# KM1M7CF13 register map
Vendor: Nuvoton Technology Corporation Japan; Series: KM1M7CF; File version: 1.0.3
CPU: CM7 r1p2, little endian, MPU, FPU, double-precision FPU, I-cache, D-cache, ITCM, DTCM, 4 interrupt priority bits
Registers are 32-bit, read-write, no defined reset value unless marked. A register's access mark holds for its fields unless they carry their own. Offsets are from the block's base; [hi:lo] are bit positions; {n}, {i} and the like mark numbered series; 'fields as' and 'values as' point back to an identical list.

## MFA — Multi Feedback Assist
Base 0x40025000
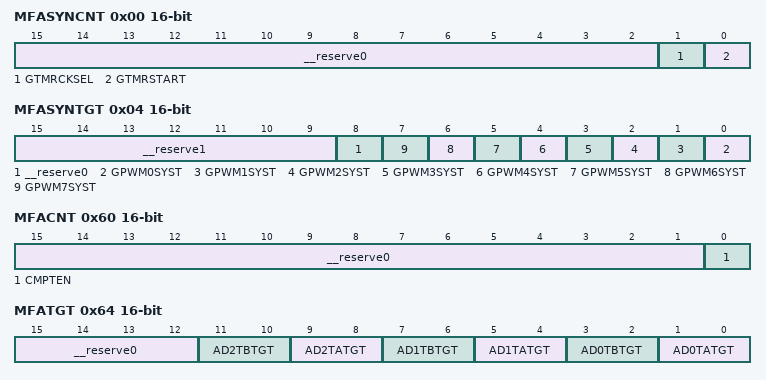
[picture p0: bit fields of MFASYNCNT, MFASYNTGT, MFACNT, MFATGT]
0x00 MFASYNCNT 16-bit access per field — Synchronous Start Control Register
  [15:2] __reserve0 ro — "0" is always read out.
  [1] GTMRCKSEL rw — Selection of count clock at global timer
  [0] GTMRSTART rw — Enable global timer operation
0x04 MFASYNTGT 16-bit access per field — Synchronous Start Target Selection Register
  [15:9] __reserve1 ro — "0" is always read out.
  [8] __reserve0 rw — This bit must be set to "0".
  [n] GPWM{n}SYST rw (n=0..7) — GPWM{n} synchronous start selection
0x08 MFAGTIMERSET 16-bit — Global Timer Cycle Set Register
  [15:0] GTIMERST — Set global timer count cycle
{0x10+4i} MFAGPWM{i}DLY 16-bit (i=0..7) — GPWM{i} Synchronous Start Timing set Register
  [15:0] GPWMnDST — Set the count value of the global timer that starts GPWMn.
0x60 MFACNT 16-bit access per field — Conflict Detection Control Register
  [15:1] __reserve0 ro — "0" is always read out.
  [0] CMPTEN rw — Enable operation of Conflict detection/Automatic avoidance function
0x64 MFATGT 16-bit access per field — Conflict Detection A/D Conversion Start Trigger Selection Register
  [15:12] __reserve0 ro — "0" is always read out.
  [11:10] AD2TBTGT rw — Selection of conflict detection and avoidance operation of A/D2 conversion start trigger B
  [9:8] AD2TATGT rw — Selection of conflict detection and avoidance operation of A/D2 conversion start trigger A
  [7:6] AD1TBTGT rw — Selection of conflict detection and avoidance operation of A/D1 conversion start trigger B
  [5:4] AD1TATGT rw — Selection of conflict detection and avoidance operation of A/D1 conversion start trigger A
  [3:2] AD0TBTGT rw — Selection of conflict detection and avoidance operation of A/D0 conversion start trigger B
  [1:0] AD0TATGT rw — Selection of conflict detection and avoidance operation of A/D0 conversion start trigger A
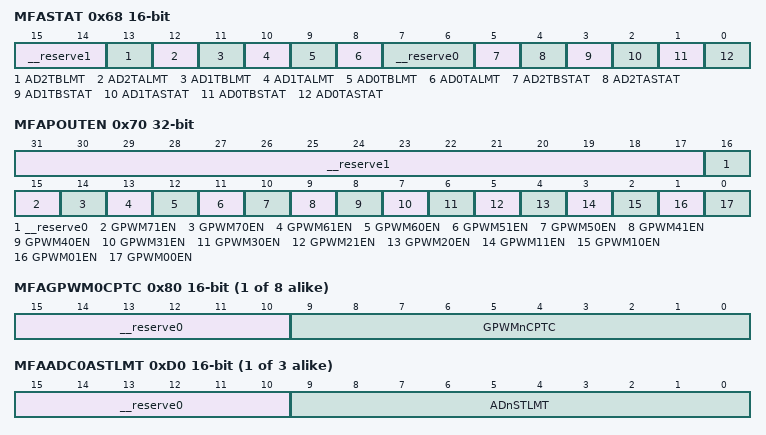
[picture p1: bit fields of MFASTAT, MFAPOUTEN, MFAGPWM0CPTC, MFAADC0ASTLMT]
0x68 MFASTAT 16-bit ro — Conflict Detection Status Register
  [15:14] __reserve1 — "0" is always read out.
  [13] AD2TBLMT — Delay status of A/D2 conversion start trigger B
  [12] AD2TALMT — Delay status of A/D2 conversion start trigger A
  [11] AD1TBLMT — Delay status of A/D1 conversion start trigger B
  [10] AD1TALMT — Delay status of A/D1 conversion start trigger A
  [9] AD0TBLMT — Delay status of A/D0 conversion start trigger B
  [8] AD0TALMT — Delay status of A/D0 conversion start trigger A
  [7:6] __reserve0 — "0" is always read out.
  [5] AD2TBSTAT — Conflict detection of A/D2 conversion start trigger B
  [4] AD2TASTAT — Conflict detection of A/D2 conversion start trigger A
  [3] AD1TBSTAT — Conflict detection of A/D1 conversion start trigger B
  [2] AD1TASTAT — Conflict detection of A/D1 conversion start trigger A
  [1] AD0TBSTAT — Conflict detection of A/D0 conversion start trigger B
  [0] AD0TASTAT — Conflict detection of A/D0 conversion start trigger A
0x70 MFAPOUTEN access per field — Conflict Detection Timer Output Selection Register
  [31:17] __reserve1 ro — "0" is always read out.
  [16] __reserve0 rw — This bit must be set to "0".
  [15] GPWM71EN rw — GPWM71 output conflict detection target pin selection
  [14] GPWM70EN rw — GPWM70 output conflict detection target pin selection
  [13] GPWM61EN rw — GPWM61 output conflict detection target pin selection
  [12] GPWM60EN rw — GPWM60 output conflict detection target pin selection
  [11] GPWM51EN rw — GPWM51 output conflict detection target pin selection
  [10] GPWM50EN rw — GPWM50 output conflict detection target pin selection
  [9] GPWM41EN rw — GPWM41 output conflict detection target pin selection
  [8] GPWM40EN rw — GPWM40 output conflict detection target pin selection
  [7] GPWM31EN rw — GPWM31 output conflict detection target pin selection
  [6] GPWM30EN rw — GPWM30 output conflict detection target pin selection
  [5] GPWM21EN rw — GPWM21 output conflict detection target pin selection
  [4] GPWM20EN rw — GPWM20 output conflict detection target pin selection
  [3] GPWM11EN rw — GPWM11 output conflict detection target pin selection
  [2] GPWM10EN rw — GPWM10 output conflict detection target pin selection
  [1] GPWM01EN rw — GPWM01 output conflict detection target pin selection
  [0] GPWM00EN rw — GPWM00 output conflict detection target pin selection
{0x80+4i} MFAGPWM{i}CPTC 16-bit access per field (i=0..7) — GPWM{i} Conflict Detection Period set Register
  [15:10] __reserve0 ro — "0" is always read out.
  [9:0] GPWMnCPTC rw — Set conflict detection period of GPWMn output
{0xD0+8i} MFAADC{i}ASTLMT 16-bit access per field (i=0..2) — A/D{i}A Conversion Start Trigger Avoidance Limit Set Register
  [15:10] __reserve0 ro — "0" is always read out.
  [9:0] ADnSTLMT rw — Set avoidance limit period of A/Dn conversion start trigger
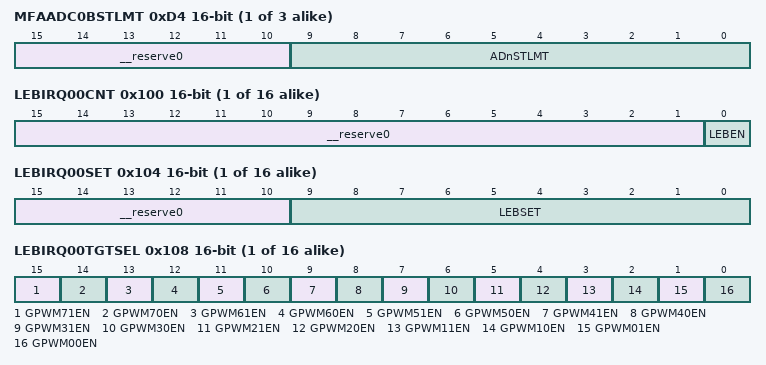
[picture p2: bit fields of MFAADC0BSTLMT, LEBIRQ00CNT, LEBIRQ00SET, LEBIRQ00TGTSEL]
{0xD4+8i} MFAADC{i}BSTLMT 16-bit access per field (i=0..2) — A/D{i}B Conversion Start Trigger Avoidance Limit Set Register
  fields as MFAADC0ASTLMT
{0x100+0x10*i} LEBIRQ{i:02}CNT 16-bit access per field (i=0..15) — IRQ{i:02} Blanking Control Register
  [15:1] __reserve0 ro — "0" is always read out.
  [0] LEBEN rw — Enable blanking function operation
{0x104+0x10*i} LEBIRQ{i:02}SET 16-bit access per field (i=0..15) — IRQ{i:02} Blanking Set Register
  [15:10] __reserve0 ro — "0" is always read out.
  [9:0] LEBSET rw — Set blanking period.
{0x108+0x10*i} LEBIRQ{i:02}TGTSEL 16-bit (i=0..15) — IRQ{i:02} Blanking Target Port Set Register
  [15] GPWM71EN — GPWM71 output blanking target pin selection
  [14] GPWM70EN — GPWM70 output blanking target pin selection
  [13] GPWM61EN — GPWM61 output blanking target pin selection
  [12] GPWM60EN — GPWM60 output blanking target pin selection
  [11] GPWM51EN — GPWM51 output blanking target pin selection
  [10] GPWM50EN — GPWM50 output blanking target pin selection
  [9] GPWM41EN — GPWM41 output blanking target pin selection
  [8] GPWM40EN — GPWM40 output blanking target pin selection
  [7] GPWM31EN — GPWM31 output blanking target pin selection
  [6] GPWM30EN — GPWM30 output blanking target pin selection
  [5] GPWM21EN — GPWM21 output blanking target pin selection
  [4] GPWM20EN — GPWM20 output blanking target pin selection
  [3] GPWM11EN — GPWM11 output blanking target pin selection
  [2] GPWM10EN — GPWM10 output blanking target pin selection
  [1] GPWM01EN — GPWM01 output blanking target pin selection
  [0] GPWM00EN — GPWM00 output blanking target pin selection
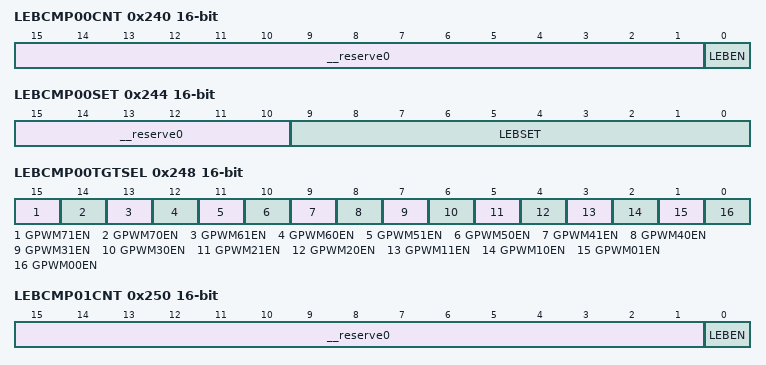
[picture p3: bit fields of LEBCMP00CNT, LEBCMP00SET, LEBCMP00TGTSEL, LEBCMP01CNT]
0x240 LEBCMP00CNT 16-bit access per field — CMP00 Blanking Control Register
  fields as LEBIRQ00CNT
0x244 LEBCMP00SET 16-bit access per field — CMP00 Blanking Set Register
  fields as LEBIRQ00SET
0x248 LEBCMP00TGTSEL 16-bit — CMP00 Blanking Target Port Set Register
  fields as LEBIRQ00TGTSEL
0x250 LEBCMP01CNT 16-bit access per field — CMP01 Blanking Control Register
  fields as LEBIRQ00CNT
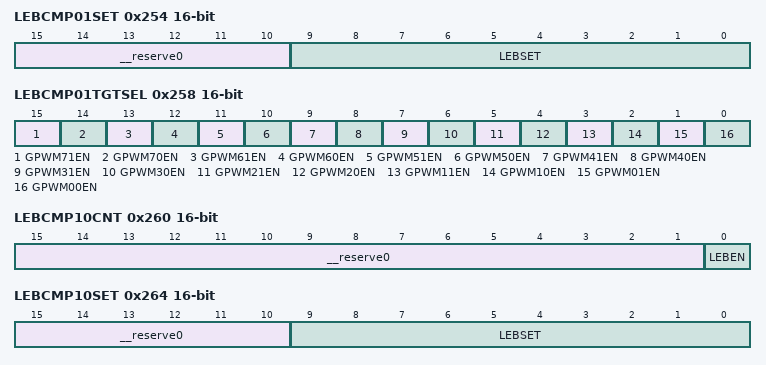
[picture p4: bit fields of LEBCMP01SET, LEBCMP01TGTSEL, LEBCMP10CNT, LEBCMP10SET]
0x254 LEBCMP01SET 16-bit access per field — CMP01 Blanking Set Register
  fields as LEBIRQ00SET
0x258 LEBCMP01TGTSEL 16-bit — CMP01 Blanking Target Port Set Register
  fields as LEBIRQ00TGTSEL
0x260 LEBCMP10CNT 16-bit access per field — CMP10 Blanking Control Register
  fields as LEBIRQ00CNT
0x264 LEBCMP10SET 16-bit access per field — CMP10 Blanking Set Register
  fields as LEBIRQ00SET
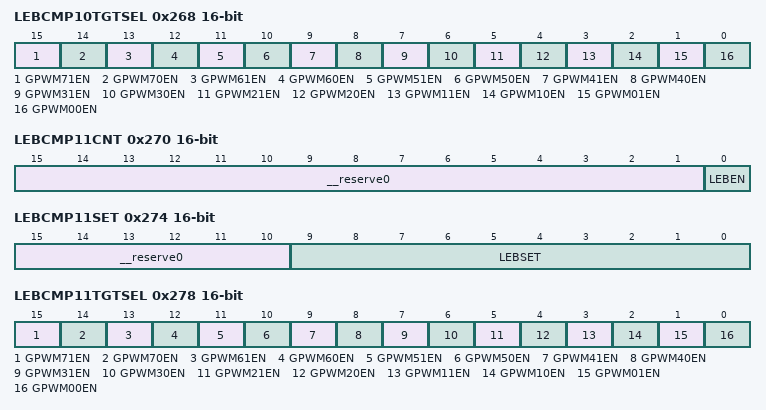
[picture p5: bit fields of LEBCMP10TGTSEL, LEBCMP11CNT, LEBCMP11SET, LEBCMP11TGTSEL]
0x268 LEBCMP10TGTSEL 16-bit — CMP10 Blanking Target Port Set Register
  fields as LEBIRQ00TGTSEL
0x270 LEBCMP11CNT 16-bit access per field — CMP11 Blanking Control Register
  fields as LEBIRQ00CNT
0x274 LEBCMP11SET 16-bit access per field — CMP11 Blanking Set Register
  fields as LEBIRQ00SET
0x278 LEBCMP11TGTSEL 16-bit — CMP11 Blanking Target Port Set Register
  fields as LEBIRQ00TGTSEL
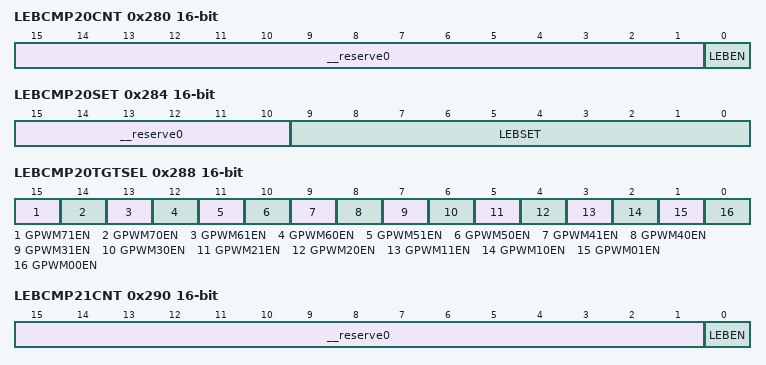
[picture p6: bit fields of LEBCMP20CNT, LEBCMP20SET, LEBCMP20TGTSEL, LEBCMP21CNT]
0x280 LEBCMP20CNT 16-bit access per field — CMP20 Blanking Control Register
  fields as LEBIRQ00CNT
0x284 LEBCMP20SET 16-bit access per field — CMP20 Blanking Set Register
  fields as LEBIRQ00SET
0x288 LEBCMP20TGTSEL 16-bit — CMP20 Blanking Target Port Set Register
  fields as LEBIRQ00TGTSEL
0x290 LEBCMP21CNT 16-bit access per field — CMP21 Blanking Control Register
  fields as LEBIRQ00CNT
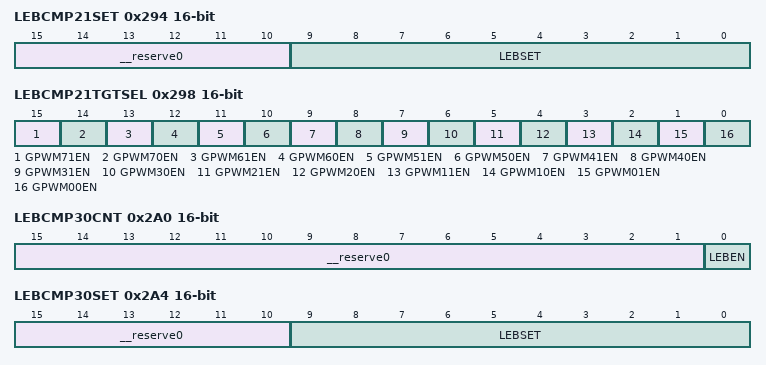
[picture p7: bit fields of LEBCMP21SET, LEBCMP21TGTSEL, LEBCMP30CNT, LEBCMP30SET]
0x294 LEBCMP21SET 16-bit access per field — CMP21 Blanking Set Register
  fields as LEBIRQ00SET
0x298 LEBCMP21TGTSEL 16-bit — CMP21 Blanking Target Port Set Register
  fields as LEBIRQ00TGTSEL
0x2A0 LEBCMP30CNT 16-bit access per field — CMP30 Blanking Control Register
  fields as LEBIRQ00CNT
0x2A4 LEBCMP30SET 16-bit access per field — CMP30 Blanking Set Register
  fields as LEBIRQ00SET
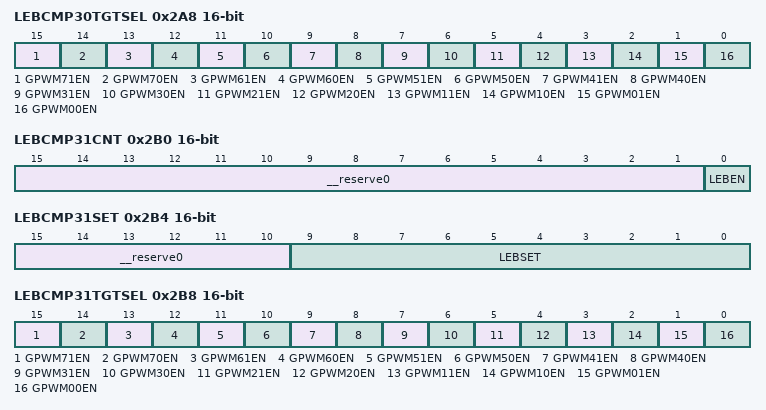
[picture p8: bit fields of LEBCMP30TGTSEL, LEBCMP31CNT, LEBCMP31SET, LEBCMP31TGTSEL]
0x2A8 LEBCMP30TGTSEL 16-bit — CMP30 Blanking Target Port Set Register
  fields as LEBIRQ00TGTSEL
0x2B0 LEBCMP31CNT 16-bit access per field — CMP31 Blanking Control Register
  fields as LEBIRQ00CNT
0x2B4 LEBCMP31SET 16-bit access per field — CMP31 Blanking Set Register
  fields as LEBIRQ00SET
0x2B8 LEBCMP31TGTSEL 16-bit — CMP31 Blanking Target Port Set Register
  fields as LEBIRQ00TGTSEL
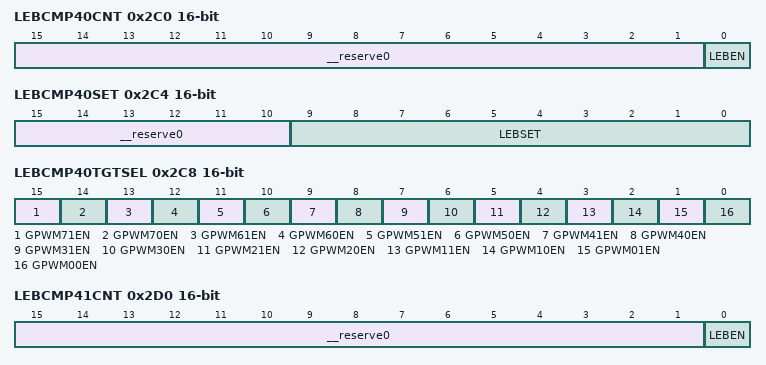
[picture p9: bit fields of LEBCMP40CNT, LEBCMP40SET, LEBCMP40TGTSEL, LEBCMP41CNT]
0x2C0 LEBCMP40CNT 16-bit access per field — CMP40 Blanking Control Register
  fields as LEBIRQ00CNT
0x2C4 LEBCMP40SET 16-bit access per field — CMP40 Blanking Set Register
  fields as LEBIRQ00SET
0x2C8 LEBCMP40TGTSEL 16-bit — CMP40 Blanking Target Port Set Register
  fields as LEBIRQ00TGTSEL
0x2D0 LEBCMP41CNT 16-bit access per field — CMP41 Blanking Control Register
  fields as LEBIRQ00CNT
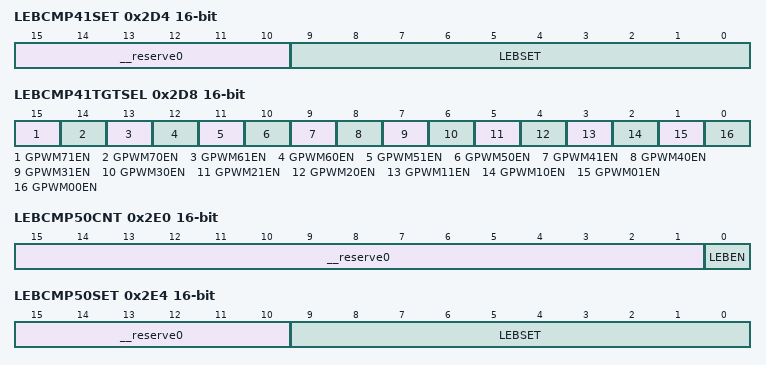
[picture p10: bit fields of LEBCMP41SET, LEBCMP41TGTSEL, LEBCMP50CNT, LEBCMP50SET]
0x2D4 LEBCMP41SET 16-bit access per field — CMP41 Blanking Set Register
  fields as LEBIRQ00SET
0x2D8 LEBCMP41TGTSEL 16-bit — CMP41 Blanking Target Port Set Register
  fields as LEBIRQ00TGTSEL
0x2E0 LEBCMP50CNT 16-bit access per field — CMP50 Blanking Control Register
  fields as LEBIRQ00CNT
0x2E4 LEBCMP50SET 16-bit access per field — CMP50 Blanking Set Register
  fields as LEBIRQ00SET
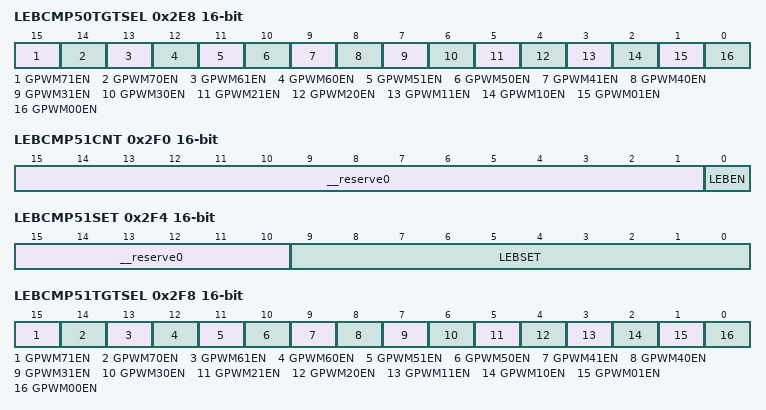
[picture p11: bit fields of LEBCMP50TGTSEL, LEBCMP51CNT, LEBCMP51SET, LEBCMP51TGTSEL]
0x2E8 LEBCMP50TGTSEL 16-bit — CMP50 Blanking Target Port Set Register
  fields as LEBIRQ00TGTSEL
0x2F0 LEBCMP51CNT 16-bit access per field — CMP51 Blanking Control Register
  fields as LEBIRQ00CNT
0x2F4 LEBCMP51SET 16-bit access per field — CMP51 Blanking Set Register
  fields as LEBIRQ00SET
0x2F8 LEBCMP51TGTSEL 16-bit — CMP51 Blanking Target Port Set Register
  fields as LEBIRQ00TGTSEL
